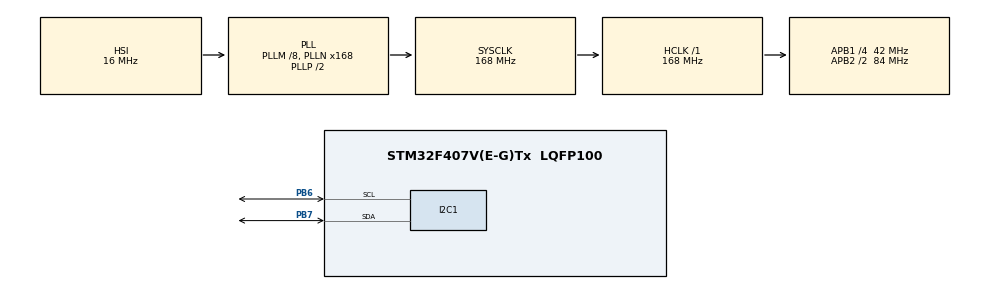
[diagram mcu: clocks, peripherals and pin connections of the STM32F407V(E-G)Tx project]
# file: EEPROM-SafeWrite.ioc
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Mcu.Family=STM32F4
Mcu.Name=STM32F407V(E-G)Tx
Mcu.Package=LQFP100
NVIC.PriorityGroup=NVIC_PRIORITYGROUP_4
PB6.Mode=I2C
PB6.Signal=I2C1_SCL
PB7.Mode=I2C
PB7.Signal=I2C1_SDA
ProjectManager.HeapSize=0x200
ProjectManager.StackSize=0x400
ProjectManager.TargetToolchain=MDK-ARM V5.27
RCC.48MHZClocksFreq_Value=84000000
RCC.AHBFreq_Value=168000000
RCC.APB1CLKDivider=RCC_HCLK_DIV4
RCC.APB1Freq_Value=42000000
RCC.APB1TimFreq_Value=84000000
RCC.APB2CLKDivider=RCC_HCLK_DIV2
RCC.APB2Freq_Value=84000000
RCC.APB2TimFreq_Value=168000000
RCC.CortexFreq_Value=168000000
RCC.HCLKFreq_Value=168000000
RCC.HSE_VALUE=25000000
RCC.HSI_VALUE=16000000
RCC.LSE_VALUE=32768
RCC.PLLM=8
RCC.PLLN=168
RCC.SYSCLKFreq_VALUE=168000000
RCC.SYSCLKSource=RCC_SYSCLKSOURCE_PLLCLK
RCC.VCOOutputFreq_Value=336000000
board=custom

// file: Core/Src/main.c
/* USER CODE BEGIN Header */
/**
  ******************************************************************************
  * @file           : main.c
  * @brief          : Main program body
  ******************************************************************************
  * @attention
  *
  * <h2><center>&copy; Copyright (c) 2023 STMicroelectronics.
  * All rights reserved.</center></h2>
  *
  * This software component is licensed by ST under BSD 3-Clause license,
  * the "License"; You may not use this file except in compliance with the
  * License. You may obtain a copy of the License at:
  *                        opensource.org/licenses/BSD-3-Clause
  *
  ******************************************************************************
  */
/* USER CODE END Header */
#include "main.h"
#include "i2c.h"
#include "gpio.h"

/* USER CODE BEGIN PD */
#define EE_DEV_ADDR           0xA0
#define EE_WRITE_DELAY        10
#define EE_PAGE_SIZE          128

/* USER CODE END PD */

/* USER CODE BEGIN PV */
static const uint8_t PATTERN[] = "01234567899876543210";
static uint8_t buf[32] = {0};
/* USER CODE END PV */

void SystemClock_Config(void);
/* USER CODE BEGIN PFP */
void EE_writeBytes(I2C_HandleTypeDef* hi2c, uint16_t addr, uint8_t* data, uint16_t len);
void EE_readBytes(I2C_HandleTypeDef* hi2c, uint16_t addr, uint8_t* data, uint16_t len);
/* USER CODE END PFP */

int main(void)
{

  /* MCU Configuration--------------------------------------------------------*/

  /* Reset of all peripherals, Initializes the Flash interface and the Systick. */
  HAL_Init();

  /* Configure the system clock */
  SystemClock_Config();

  /* Initialize all configured peripherals */
  MX_GPIO_Init();
  MX_I2C1_Init();
  /* USER CODE BEGIN 2 */

  // Legacy
  /*
  // 1: Write
  HAL_I2C_Mem_Write(&hi2c1, EE_DEV_ADDR, 120, I2C_MEMADD_SIZE_16BIT, (uint8_t*) PATTERN, sizeof(PATTERN) - 1, 1000);
  HAL_Delay(EE_WRITE_DELAY);
  // 2: Read
  HAL_I2C_Mem_Read(&hi2c1, EE_DEV_ADDR, 120, I2C_MEMADD_SIZE_16BIT, buf, sizeof(PATTERN) - 1, 1000);
  */

  // Safe
  // 1: Write
  EE_writeBytes(&hi2c1, 120, (uint8_t*) PATTERN, sizeof(PATTERN) - 1);
  // 2: Read
  EE_readBytes(&hi2c1, 120, buf, sizeof(PATTERN) - 1);

  /* USER CODE END 2 */

  /* Infinite loop */
  while (1)
  {

  }
}

void SystemClock_Config(void)
{
  RCC_OscInitTypeDef RCC_OscInitStruct = {0};
  RCC_ClkInitTypeDef RCC_ClkInitStruct = {0};

  /** Configure the main internal regulator output voltage
  */
  __HAL_RCC_PWR_CLK_ENABLE();
  __HAL_PWR_VOLTAGESCALING_CONFIG(PWR_REGULATOR_VOLTAGE_SCALE1);
  /** Initializes the RCC Oscillators according to the specified parameters
  * in the RCC_OscInitTypeDef structure.
  */
  RCC_OscInitStruct.OscillatorType = RCC_OSCILLATORTYPE_HSI;
  RCC_OscInitStruct.HSIState = RCC_HSI_ON;
  RCC_OscInitStruct.HSICalibrationValue = RCC_HSICALIBRATION_DEFAULT;
  RCC_OscInitStruct.PLL.PLLState = RCC_PLL_ON;
  RCC_OscInitStruct.PLL.PLLSource = RCC_PLLSOURCE_HSI;
  RCC_OscInitStruct.PLL.PLLM = 8;
  RCC_OscInitStruct.PLL.PLLN = 168;
  RCC_OscInitStruct.PLL.PLLP = RCC_PLLP_DIV2;
  RCC_OscInitStruct.PLL.PLLQ = 4;
  if (HAL_RCC_OscConfig(&RCC_OscInitStruct) != HAL_OK)
  {
    Error_Handler();
  }
  /** Initializes the CPU, AHB and APB buses clocks
  */
  RCC_ClkInitStruct.ClockType = RCC_CLOCKTYPE_HCLK|RCC_CLOCKTYPE_SYSCLK
                              |RCC_CLOCKTYPE_PCLK1|RCC_CLOCKTYPE_PCLK2;
  RCC_ClkInitStruct.SYSCLKSource = RCC_SYSCLKSOURCE_PLLCLK;
  RCC_ClkInitStruct.AHBCLKDivider = RCC_SYSCLK_DIV1;
  RCC_ClkInitStruct.APB1CLKDivider = RCC_HCLK_DIV4;
  RCC_ClkInitStruct.APB2CLKDivider = RCC_HCLK_DIV2;

  if (HAL_RCC_ClockConfig(&RCC_ClkInitStruct, FLASH_LATENCY_5) != HAL_OK)
  {
    Error_Handler();
  }
}

/* USER CODE BEGIN 4 */
void EE_writeBytes(I2C_HandleTypeDef* hi2c, uint16_t addr, uint8_t* data, uint16_t len) {
  uint16_t tmpLen;

  // 1: Write to Align Address
  if ((tmpLen = addr % EE_PAGE_SIZE) != 0) {
    tmpLen = EE_PAGE_SIZE - tmpLen;
    HAL_I2C_Mem_Write(hi2c, EE_DEV_ADDR, addr, I2C_MEMADD_SIZE_16BIT, data, tmpLen, 1000);
    addr += tmpLen;
    data += tmpLen;
    len -= tmpLen;
    HAL_Delay(EE_WRITE_DELAY);
  }
  // 2: Write Pages
  tmpLen = EE_PAGE_SIZE;
  while (len > EE_PAGE_SIZE) {
    HAL_I2C_Mem_Write(hi2c, EE_DEV_ADDR, addr, I2C_MEMADD_SIZE_16BIT, data, tmpLen, 1000);
    addr += tmpLen;
    data += tmpLen;
    len -= tmpLen;
    HAL_Delay(EE_WRITE_DELAY);
  }
  // 3: Write leftover
  if (len > 0) {
    HAL_I2C_Mem_Write(hi2c, EE_DEV_ADDR, addr, I2C_MEMADD_SIZE_16BIT, data, len, 1000);
    HAL_Delay(EE_WRITE_DELAY);
  }
}
void EE_readBytes(I2C_HandleTypeDef* hi2c, uint16_t addr, uint8_t* data, uint16_t len) {
  HAL_I2C_Mem_Read(hi2c, EE_DEV_ADDR, addr, I2C_MEMADD_SIZE_16BIT, data, len, 1000);
}
/* USER CODE END 4 */

void Error_Handler(void)
{
  __disable_irq();
  while (1)
  {
  }
}

/************************ (C) COPYRIGHT STMicroelectronics *****END OF FILE****/
